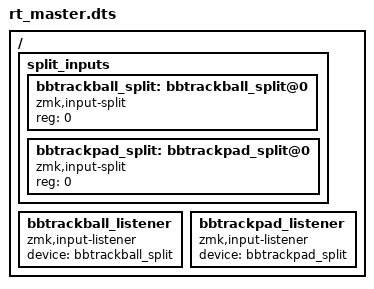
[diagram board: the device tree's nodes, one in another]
/*
 * 右半 · 主控：没有 dongle，右半自己连主机。
 *
 * Copyright (c) 2025 ZitaoTech
 * SPDX-License-Identifier: MIT
 *
 * 硬件在 rt.dtsi；本文件只加「中央侧」多出来的东西。
 *
 * 本半的小红点不走 split：listener 直接接板载设备，由 trackpoint 的
 * boards/rt_master.overlay 改写（那里同时把同名代理关掉——中央侧投递是
 * 「按 reg 找第一个匹配的代理就返回」（src/pointing/input_split.c:32-33），
 * 只认 status=okay 的代理（:27）；留一个没接 listener 的 reg=0 代理，
 * 会被对侧上报的事件撞上，白吃掉数据）。
 *
 * 对侧（左半）的模块走 split 入站：左半插的是轨迹球还是触摸板在编译期未知，
 * 所以两个代理都声明（都写 reg=0）。这是无害的：中央侧按 reg 找第一个匹配的
 * 代理投递（input_split.c:29-34），而两个 listener 都不挂 input-processors，
 * 纯粹是直通——数据落在哪个代理上，最终效果完全一样。
 * 代理在中央侧不用写 device（那个 BUILD_ASSERT 只在外设侧编译，
 * 而且 <&bbtrackball> / <&bbtrackpad> 在这块板上并不存在）。
 */

#include "rt.dtsi"

/ {
    split_inputs {
        #address-cells = <1>;
        #size-cells = <0>;

        bbtrackball_split: bbtrackball_split@0 {
            compatible = "zmk,input-split";
            reg = <0>;
        };

        bbtrackpad_split: bbtrackpad_split@0 {
            compatible = "zmk,input-split";
            reg = <0>;
        };
    };

    bbtrackball_listener: bbtrackball_listener {
        compatible = "zmk,input-listener";
        status = "okay";
        device = <&bbtrackball_split>;
    };

    bbtrackpad_listener: bbtrackpad_listener {
        compatible = "zmk,input-listener";
        status = "okay";
        device = <&bbtrackpad_split>;
    };
};

/*
 * 这里不挂 input-processors：本分支的指针语义是「指针设备跟随层」——模式由
 * 驱动自己根据按住的键位决定（默认滚轮，按住 mouse 层拇指键切鼠标移动），
 * 键位见各 shield 的 Kconfig，不需要 listener 这边做任何加工。
 */
